# K1921VG015 register map
Vendor: NIIET; Series: K1921Vxxx; File version: 1.12
UltraLowPower MCU
Registers are 32-bit, read-write, reset 0x0 unless marked. A register's access mark holds for its fields unless they carry their own. Offsets are from the block's base; lines under a group give offsets from that group; [hi:lo] are bit positions; {n}, {i} and the like mark numbered series; 'fields as' and 'values as' point back to an identical list; <NAME> marks a mode.

## Memory map
? TMR32 size 0x40 — TMR 32-bit controller registers
0x20000000 CAN size 0x3004 — CAN controller registers
0x20001000 CANMSG size 0x3005 — CAN Msg registers
0x20010000 USB size 0xC04 — USB control registers
0x20020000 CRYPTO size 0x8C — Cryptographic module registers (AES_128, AES_256, Magma, Kuznechik algorithms)
0x20030000 CRC0 size 0x14 — CRC controller registers
0x20031000 CRC1 size 0x14
0x20032000 HASH size 0x64 — HASH controller registers
0x20040000 QSPI size 0x38 — QSPI control registers
0x20050000 SPI0 size 0x28 — SPI control registers
0x20060000 SPI1 size 0x28
0x28000000 GPIOA size 0xC04 — GPIO control registers
0x28001000 GPIOB size 0xC04
0x28002000 GPIOC size 0xC04
0x30001000 TMR0 size 0x40 — TMR 16-bit controller registers
0x30002000 TMR1 size 0x40
0x30003000 TMR2 size 0x40
0x30004000 TRNG size 0x104 — Random Number Generators (TRNG) control registers
0x30005000 I2C size 0x2C — I2C controller registers
0x30006000 UART0 size 0x4C — UART control registers
0x30007000 UART1 size 0x4C
0x30008000 UART2 size 0x4C
0x30009000 UART3 size 0x4C
0x3000A000 UART4 size 0x4C
0x3000B000 WDT size 0xC04 — Watchdog control registers
0x3000C000 DMA size 0x58 — DMA control registers
0x3000D000 FLASH size 0xCC — Mainflash control registers
0x3000E000 RCU size 0xC4 — Reset and clock unit registers
0x3000F000 PMUSYS size 0x124 — Power management unit registers
0x30010000 ADCSAR size 0x6A4 — ADC SAR control registers
0x30011000 TSENS size 0x4 — Temperature sensor controller registers
0x30012000 ADCSD size 0x64 — ADC SAR control registers
0x38010000 CMP size 0x20 — CMP controller registers
0x38011000 PMURTC size 0xC8 — RTC controller registers
0x38012000 IWDT size 0xC04 — Watchdog control registers

## Interrupts
1 WDT — Watchdog timer interrupt
2 CAN0 (CAN) — CAN0 interrupt
3 CAN1 (CAN) — CAN1 interrupt
4 USB — USB interrupt
7 TMR0 — Timer 0 interrupt
8 TMR1 — Timer 1 interrupt
9 TMR2 — Timer 2 interrupt
10 QSPI — QSPI interrupt
11 SPI0 — SPI0 interrupt
12 SPI1 — SPI1 interrupt
{n+13} DMA{n} (DMA) (n=0..7) — DMA channel {3n},{3n+1},{3n+2} interrupt
21 I2C — I2C interrupt
22 UART0 — UART0 interrupt
23 UART1 — UART1 interrupt
24 UART2 — UART2 interrupt
25 UART3 — UART3 interrupt
26 UART4 — UART4 interrupt
28 TRNG — TRNG interrupt
30 CMP — CMP interrupt
31 PMURTC — PMURTC interrupt

## PMUSYS — Power management unit registers
Base 0x3000F000
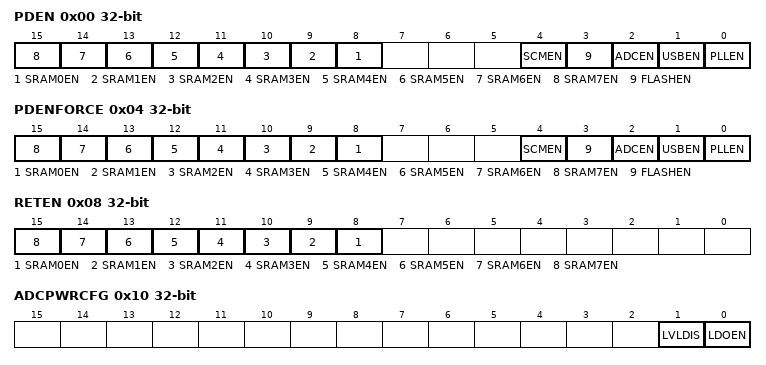
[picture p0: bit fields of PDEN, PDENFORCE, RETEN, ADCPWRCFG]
0x00 PDEN — PMU Core Periph powerdown register
  [n+8] SRAM{n}EN (n=0..7) — SRAM0 {32n}-{32n+32}k powerdown
  [4] SCMEN — System clock manager powerdown after WFI command
  [3] FLASHEN — FLASH powerdown after WFI command
  [2] ADCEN — ADC powerdown after WFI command
  [1] USBEN — USB powerdown after WFI command
  [0] PLLEN — PLL powerdown after WFI command
0x04 PDENFORCE — PMU Core Periph powerdown Force register
  [n+8] SRAM{n}EN (n=0..7) — SRAM0 {32n}-{32n+32}k powerdown
  [4] SCMEN — this bit write down no (always read 0)
  [3] FLASHEN — FLASH powerdown after write this bit
  [2] ADCEN — ADC powerdown after write this bit
  [1] USBEN — USB powerdown after write this bit
  [0] PLLEN — PLL powerdown after write this bit
0x08 RETEN — PMU Enable SRAM retention register
  [n+8] SRAM{n}EN (n=0..7) — Retention SRAM0 block
0x10 ADCPWRCFG — SAR ADC Powerdown configuration register
  [1] LVLDIS — Disable ADC level-shifters to go into deep LP mode
  [0] LDOEN — Enable ADC module Low Drop Out Regulator (LDO)
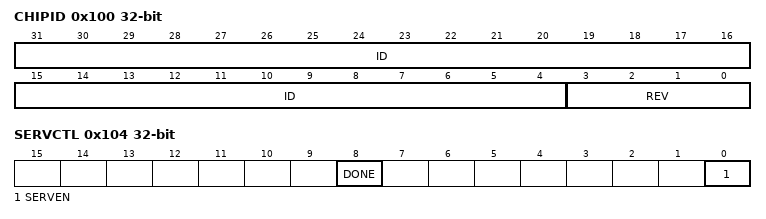
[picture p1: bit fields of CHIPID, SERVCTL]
0x100 CHIPID ro — Chip identifier register
  [31:4] ID — Chip identifier
  [3:0] REV — Revision
0x104 SERVCTL — Service mode control register
  [8] DONE — WR_serv_all_erase_req__RD_serv_done
  [0] SERVEN — SERV_EN_STAT
{0x110+4i} UID[{i}] (i=0..3) group
  0x00 UID ro — Unique ID register 128 bit
    [31:0] VAL

## Licence text in the file
THIS SOFTWARE IS PROVIDED "AS IS". NO WARRANTIES, WHETHER EXPRESS, IMPLIED. OR STATUTORY, INCLUDING, BUT NOT LIMITED TO, IMPLIED WARRANTIES OF. MERCHANTABILITY AND FITNESS FOR A PARTICULAR PURPOSE APPLY TO THIS SOFTWARE. ARM SHALL NOT, IN ANY CIRCUMSTANCES, BE LIABLE FOR SPECIAL, INCIDENTAL, OR. CONSEQUENTIAL DAMAGES, FOR ANY REASON WHATSOEVER.
